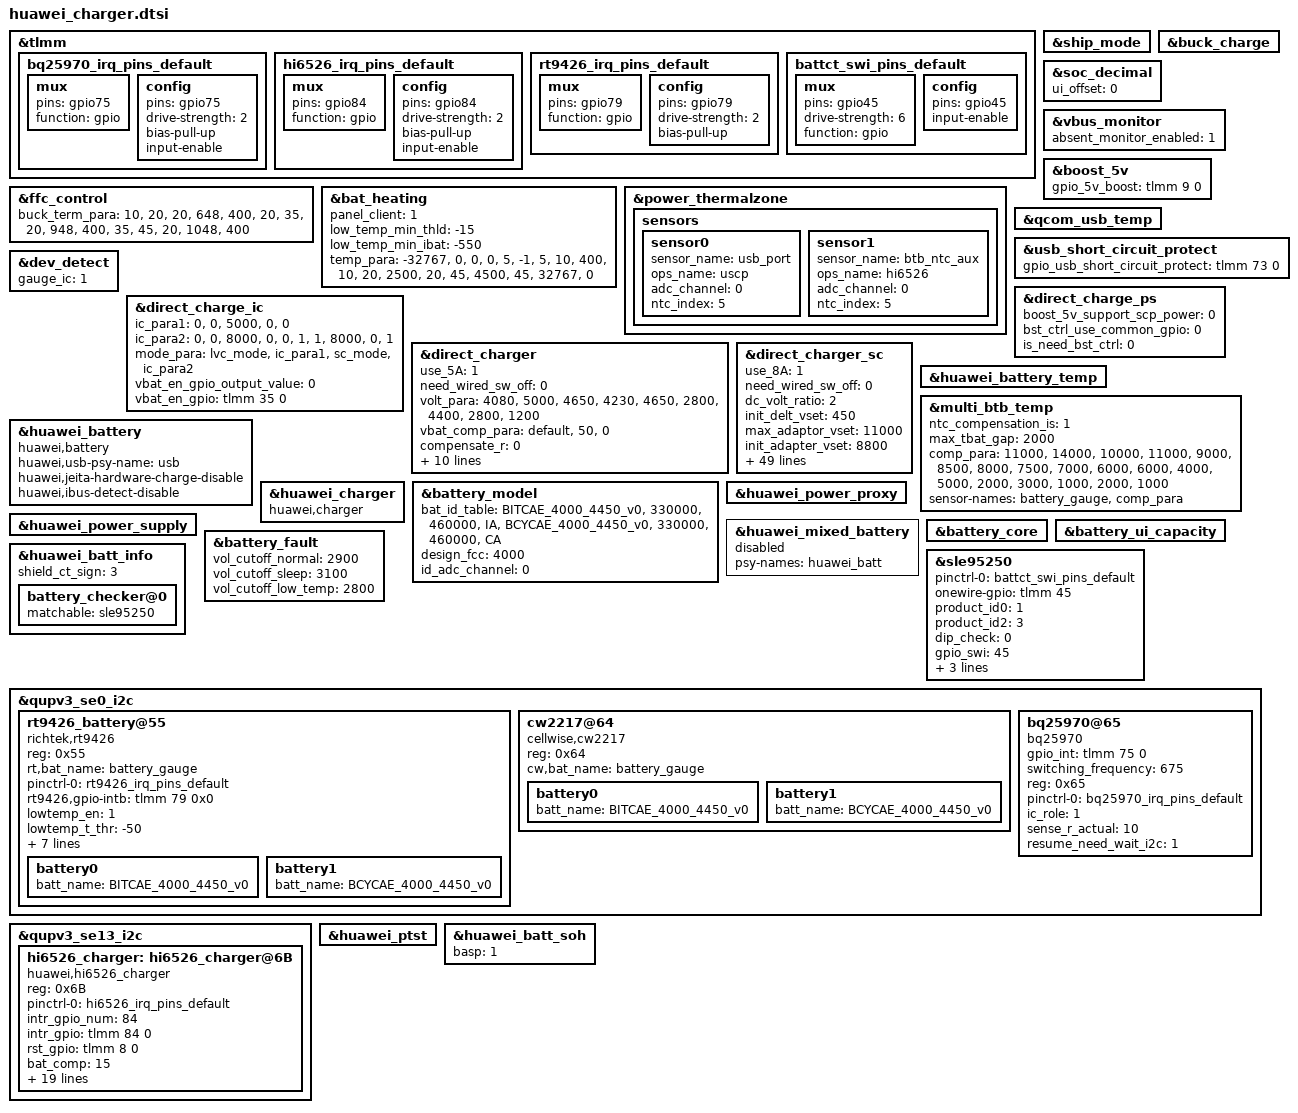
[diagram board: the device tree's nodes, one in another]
&tlmm {
	bq25970_irq_pins_default: bq25970_irq_pins_default {
		mux {
			pins = "gpio75";
			function = "gpio";
		};
		config {
			pins = "gpio75";
			drive-strength = <2>;
			bias-pull-up;
			input-enable;
		};
	};

	hi6526_irq_pins_default: hi6526_irq_pins_default {
		mux {
			pins = "gpio84";
			function = "gpio";
		};
		config {
			pins = "gpio84";
			drive-strength = <2>;
			bias-pull-up;
			input-enable;
		};
	};

	rt9426_irq_pins_default: rt9426_irq_pins_default {
		mux {
			pins = "gpio79";
			function = "gpio";
		};
		config {
			pins = "gpio79";
			drive-strength = <2>;
			bias-pull-up;
		};
	};

	battct_swi_pins_default: battct_swi_pins_default {
		mux {
			pins = "gpio45";
			drive-strength = <6>;
			function = "gpio";
		};
		config {
			pins = "gpio45";
			input-enable;
		};
	};
};

&ship_mode {
	status = "ok";
};

&buck_charge {
	status = "ok";
};

&ffc_control {
	status = "ok";
	buck_term_para =
		"10", "20", "20", "648", "400",
		"20", "35", "20", "948", "400",
		"35", "45", "20", "1048", "400";
};

&bat_heating {
	panel_client = "1";
	low_temp_min_thld = "-15";
	low_temp_min_ibat = "-550";
	temp_para =
		"-32767", "0", "0",
		"0", "5", "-1",
		"5", "10", "400",
		"10", "20", "2500",
		"20", "45", "4500",
		"45", "32767", "0";
	status = "ok";
};

&soc_decimal {
	ui_offset = <0>;
	status = "ok";
};

&vbus_monitor {
	status = "ok";
	absent_monitor_enabled = <1>;
};

&boost_5v {
	gpio_5v_boost = <&tlmm 9 0>; /* GPIO_09 */
	status = "ok";
};

&power_thermalzone {
	status = "ok";
	sensors{
		sensor0 {
			sensor_name = "usb_port";
			ops_name = "uscp";
			adc_channel = <0>;
			ntc_index = <5>;
		};
		sensor1 {
			sensor_name = "btb_ntc_aux";
			ops_name = "hi6526";
			adc_channel = <0>;
			ntc_index = <5>;
		};
	};
};

&qcom_usb_temp {
	status = "ok";
};

&usb_short_circuit_protect {
	gpio_usb_short_circuit_protect = <&tlmm 73 0>; /* GPIO_073 */
	status = "ok";
};

&dev_detect {
	gauge_ic = <1>;
};

&direct_charge_ps {
	boost_5v_support_scp_power = <0>;
	bst_ctrl_use_common_gpio = <0>;
	is_need_bst_ctrl = <0>;
	status = "ok";
};

&direct_charge_ic {
	/* The IC_PARA table is used to find the relationship between chip and path */
	/* the chip's current passing capacity */
	/* and the sampling points of battery voltage and current */
	/* ic_index path_index max_ibat ibat_sample_point vbat_sample_point */
	/* ic_index  path_index  max_ibat  ibat_sample_point  vbat_sample_point */
	ic_para1 =
		"0", "0", "5000", "0", "0";
	ic_para2 =
		"0", "0", "8000", "0", "0",
		"1", "1", "8000", "0", "1";
	mode_para =
		"lvc_mode", "ic_para1",
		"sc_mode", "ic_para2";
	vbat_en_gpio_output_value = <0>;
	vbat_en_gpio = <&tlmm 35 0>;
	status = "ok";
};

&direct_charger {
	use_5A = <1>;
	need_wired_sw_off = <0>;
	volt_para =
		"4080", "5000", "4650",
		"4230", "4650", "2800",
		"4400", "2800", "1200";
	vbat_comp_para =
		"default", "50", "0";
	compensate_r = <0>;
	cc_cable_detect_enable = <1>;
	full_path_res_max = <220>;
	scp_work_on_charger = <1>;
	standard_cable_full_path_res_max = <260>;
	first_cc_stage_timer_in_min = <5>;
	stage_need_to_jump = "1";
	low_temp_hysteresis = <5>;
	temp_para =
		"-32767", "10", "0",
		"10", "45", "5000",
		"45", "32767", "0";
	rt_test_para =
		"2000", "105"; /* rt_curr_th rt_test_time */
	status = "ok";
};

&direct_charger_sc {
	use_8A = <1>;
	need_wired_sw_off = <0>;
	dc_volt_ratio = <2>;
	init_delt_vset = <450>;
	max_adaptor_vset = <11000>;
	init_adapter_vset = <8800>;
	vol_err_th = <500>;
	adaptor_leakage_current_th = <600>;
	vstep = <20>;
	min_dc_bat_vol = <3500>;
	max_dc_bat_vol = <4380>;
	max_current_for_none_standard_cable = <6000>;
	adaptor_antifake_check_enable = <1>;
	adaptor_antifake_key_index = <2>;
	support_multi_ic = <1>;
	multi_ic_ibat_th = <4000>;
	second_resist_check_en = <1>;
	ui_max_pwr = <40000>;
	product_max_pwr = <66000>;
	volt_para =
		"4150", "8000", "6600",
		"4250", "6600", "4400",
		"4300", "4400", "3000",
		"4400", "3000", "2000";
	volt_para1 =
		"4180", "12800", "8000",
		"4300", "8000", "6400",
		"4380", "6400", "5100",
		"4450", "5100", "4300",
		"4470", "4300", "948";
	volt_para2 =
		"4180", "12800", "8000",
		"4300", "8000", "6400",
		"4380", "6400", "5100",
		"4450", "5100", "4300",
		"4470", "4300", "1048";
	time_para =
		"500", "6300",
		"400", "7000",
		"300", "8000",
		"120", "10000",
		"0", "12400";
	bat_para =
		"default", "10", "20", "volt_para",
		"default", "20", "35", "volt_para1",
		"default", "35", "45", "volt_para2",
		"CAE", "10", "20", "volt_para",
		"CAE", "20", "35", "volt_para1",
		"CAE", "35", "45", "volt_para2";
	vbat_comp_para =
		"default", "45", "0",
		"bq25970", "44", "19",
		"rt9759", "44", "34";
	vstep_para =
		"2000", "80";
	compensate_r = <0>;
	cc_cable_detect_enable = <1>;
	full_path_res_max = <450>;
	scp_work_on_charger = <1>;
	standard_cable_full_path_res_max = <280>;
	first_cc_stage_timer_in_min = <10>;
	stage_need_to_jump = "-1";
	low_temp_hysteresis = <5>;
	current_ratio =
		"3", "5", "16", "2", "-1",
		"3", "6", "13", "1", "8000",
		"0", "6", "13", "0", "0";
	vbat_error =
		"3", "120", "2", "-1",
		"3", "80", "1", "0";
	temp_para =
		"-32767", "10", "0",
		"10", "46", "12800",
		"46", "32767", "0";
	resist_para =
		"0", "260", "6000",
		"260", "450", "4000";
	std_resist_para =
		"0", "300", "0",
		"300", "450", "4000";
	second_resist_para =
		"0", "180", "0",
		"180", "450", "8000";
	ctc_second_resist_para =
		"0", "250", "0",
		"250", "450", "8000";
	rt_test_para =
		/* first:sc second:mainsc third:auxsc */
		"3000", "105",
		"3000", "105",
		"3000", "105";
	status = "ok";
};

&huawei_battery_temp {
	status = "ok";
};

&multi_btb_temp {
	status = "ok";
	ntc_compensation_is = <1>;
	max_tbat_gap = <2000>;
	comp_para =
		"11000", "14000",
		"10000", "11000",
		"9000", "8500",
		"8000", "7500",
		"7000", "6000",
		"6000", "4000",
		"5000", "2000",
		"3000", "1000",
		"2000", "1000";
	sensor-names =
		"battery_gauge", "comp_para";
};

&huawei_battery {
	compatible = "huawei,battery";
	status = "ok";
	huawei,usb-psy-name = "usb";
	huawei,jeita-hardware-charge-disable;
	huawei,ibus-detect-disable;
};

&huawei_charger {
	compatible = "huawei,charger";
	status = "ok";
};


&battery_model {
	bat_id_table =
		"BITCAE_4000_4450_v0", "330000", "460000", "IA",
		"BCYCAE_4000_4450_v0", "330000", "460000", "CA";
	design_fcc = <4000>;
	id_adc_channel = <0>; /* useless but necessary for Qcom, set 0 as default */
	status = "ok";
};

&huawei_power_proxy {
	status = "ok";
};

&huawei_power_supply {
	 status = "ok";
};

&huawei_mixed_battery {
	psy-names = "huawei_batt";
	status = "disabled";
};

&battery_core {
	status = "ok";
};

&battery_ui_capacity {
	status = "ok";
};

&battery_fault {
	vol_cutoff_normal = <2900>;
	vol_cutoff_sleep = <3100>;
	vol_cutoff_low_temp = <2800>;
	status = "ok";
};

&sle95250 {
	pinctrl-names = "default";
	pinctrl-0 = <&battct_swi_pins_default>;
	onewire-gpio = <&tlmm 45 0>;
	product_id0 = <1>;
	product_id2 = <3>;
	dip_check = <0>;
	gpio_swi = <45>;
	gpio_swi_drv = <2>;
	tau = /bits/ 8 <0xa>;
	tau_fastboot = <7>;
	status = "ok";
};

&huawei_batt_info {
	status = "ok";
	shield_ct_sign = <3>;
	battery_checker@0 {
		matchable = <&sle95250>;
		status = "ok";
	};
};

&qupv3_se0_i2c {
	#address-cells = <1>;
	#size-cells = <0>;
	status = "ok";
	rt9426_battery@55{
		reg = <0x55>;
		compatible = "richtek,rt9426";
		rt,bat_name = "battery_gauge";
		pinctrl-names = "default";
		pinctrl-0 = <&rt9426_irq_pins_default>;
		rt9426,gpio-intb = <&tlmm 79 0x0>;
		lowtemp_en = <1>;
		lowtemp_t_thr = "-50";
		lowtemp_edv_thr = <0x64>;
		need_reset_version = <9>;
		rt_config_ver = <12>;
		ntc_compensation_is = <1>;
		ntc_temp_compensation_para =
			"11000", "110",
			"10000", "100",
			"9000", "80",
			"8000", "60",
			"7000", "50",
			"6000", "40",
			"5000", "30",
			"3000", "20",
			"2000", "10";
		status = "ok";
		battery0{
			batt_name = "BITCAE_4000_4450_v0";
			#include "../../../huawei_charger/rt9426_BITCAE_4450mAh_AMBER_BT185.dtsi"
		};
		battery1{
			batt_name = "BCYCAE_4000_4450_v0";
			#include "../../../huawei_charger/rt9426_BITCAE_4450mAh_AMBER_BT185.dtsi"
		};
	};

	cw2217@64 {
		compatible = "cellwise,cw2217";
		reg = <0x64>;
		cw,bat_name = "battery_gauge";
		status = "ok";
		battery0{
			batt_name = "BITCAE_4000_4450_v0";
			#include "../../../huawei_charger/cw2217_BITCAE_4000mAh_4V45_BT185.dtsi"
		};
		battery1{
			batt_name = "BCYCAE_4000_4450_v0";
			#include "../../../huawei_charger/cw2217_BCYCAE_4000mAh_4V45_BT185.dtsi"
		};
	};

	bq25970@65 {
		compatible = "bq25970";
		gpio_int = <&tlmm 75 0>;
		switching_frequency = <675>;
		reg = <0x65>;
		pinctrl-names = "default";
		pinctrl-0 = <&bq25970_irq_pins_default>;
		ic_role = <1>;
		sense_r_actual = <10>;
		resume_need_wait_i2c = <1>;
		status = "ok";
	};
};

&qupv3_se13_i2c {
	status = "ok";

	hi6526_charger: hi6526_charger@6B {
		status = "ok";
		compatible = "huawei,hi6526_charger";
		reg = <0x6B>;
		pinctrl-names = "hi6526_irq_pins_default";
		pinctrl-0 = <&hi6526_irq_pins_default>;
		intr_gpio_num = <84>;
		intr_gpio = <&tlmm 84 0>;
		rst_gpio = <&tlmm 8 0>;
		bat_comp = <15>;
		vclamp = <150>;
		adc_channel_vbat_sys = <14>;
		fcp_support = <1>;
		scp_support = <1>;
		lvc_ibat_regulator = <12200>;
		lvc_vbat_regulator = <4500>;
		lvc_vout_regulator = <4550>;
		lvc_ibus_regulator = <5600>;
		sc_ibat_regulator = <12200>;
		sc_vbat_regulator = <4500>;
		sc_vout_regulator = <4590>;
		sc_ibus_regulator = <5600>;
		lvc_vusb2vbus_drop_en = <1>;
		sc_vusb2vbus_drop_en = <1>;
		/* loop mode must be turned off, if temperature channels need to be acquired */
		adc_single_mode_en = <0>;
		adc_tsbat_support = <0>;
		ico_current_mode = <0>;
		vusb_uv_flag = <1>;
                r_coul_mohm = <1>;
	};
};

&huawei_ptst {
	status = "ok";
};

&huawei_batt_soh {
	basp = <1>;
	status = "ok";
};
